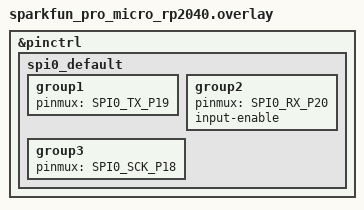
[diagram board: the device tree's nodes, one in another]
&pinctrl {
    spi0_default: spi0_default {
		group1 {
			pinmux = <SPI0_TX_P19>;
		};
		group2 {
			pinmux = <SPI0_RX_P20>;
			input-enable;
		};
		group3 {
			pinmux = <SPI0_SCK_P18>;
		};
    };
};
